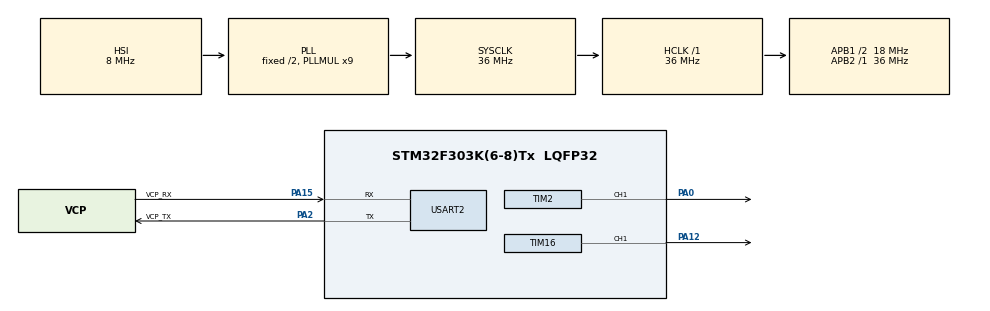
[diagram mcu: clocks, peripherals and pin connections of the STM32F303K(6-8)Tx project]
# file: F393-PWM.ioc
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Mcu.Family=STM32F3
Mcu.Name=STM32F303K(6-8)Tx
Mcu.Package=LQFP32
NVIC.PriorityGroup=NVIC_PRIORITYGROUP_4
PA0.Signal=S_TIM2_CH1_ETR
PA12.Signal=S_TIM16_CH1
PA13.GPIO_Label=SWDIO
PA13.Mode=Serial_Wire
PA13.Signal=SYS_JTMS-SWDIO
PA14.GPIO_Label=SWCLK
PA14.Mode=Serial_Wire
PA14.Signal=SYS_JTCK-SWCLK
PA15.GPIO_Label=VCP_RX
PA15.Mode=Asynchronous
PA15.Signal=USART2_RX
PA2.GPIO_Label=VCP_TX
PA2.Mode=Asynchronous
PA2.Signal=USART2_TX
PF0\ /\ OSC_IN.GPIO_Label=MCO
PF0\ /\ OSC_IN.Signal=RCC_OSC_IN
ProjectManager.HeapSize=0x200
ProjectManager.StackSize=0x400
ProjectManager.TargetToolchain=STM32CubeIDE
RCC.AHBFreq_Value=36000000
RCC.APB1CLKDivider=RCC_HCLK_DIV2
RCC.APB1Freq_Value=18000000
RCC.APB1TimFreq_Value=36000000
RCC.APB2Freq_Value=36000000
RCC.APB2TimFreq_Value=36000000
RCC.CortexFreq_Value=36000000
RCC.HCLKFreq_Value=36000000
RCC.HSE_VALUE=8000000
RCC.HSI_VALUE=8000000
RCC.PLLMUL=RCC_PLL_MUL9
RCC.SYSCLKFreq_VALUE=36000000
RCC.SYSCLKSourceVirtual=RCC_SYSCLKSOURCE_PLLCLK
SH.S_TIM16_CH1.0=TIM16_CH1,PWM Generation1 CH1
SH.S_TIM2_CH1_ETR.0=TIM2_CH1,PWM Generation1 CH1
TIM16.AutoReloadPreload=TIM_AUTORELOAD_PRELOAD_ENABLE
TIM16.Channel=TIM_CHANNEL_1
TIM16.Period=65535
TIM2.AutoReloadPreload=TIM_AUTORELOAD_PRELOAD_ENABLE
TIM2.Channel-PWM\ Generation1\ CH1=TIM_CHANNEL_1
TIM2.OCFastMode_PWM-PWM\ Generation1\ CH1=TIM_OCFAST_ENABLE
TIM2.OCPolarity_1=TIM_OCPOLARITY_HIGH
TIM2.Period=65535
USART2.VirtualMode-Asynchronous=VM_ASYNC
VP_TIM16_VS_ClockSourceINT.Mode=Enable_Timer
VP_TIM2_VS_ClockSourceINT.Mode=Internal
board=NUCLEO-F303K8

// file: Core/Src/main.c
/* USER CODE BEGIN Header */
/**
 ******************************************************************************
 * @file           : main.c
 * @brief          : Main program body
 ******************************************************************************
 * @attention
 *
 * Copyright (c) 2023 STMicroelectronics.
 * All rights reserved.
 *
 * This software is licensed under terms that can be found in the LICENSE file
 * in the root directory of this software component.
 * If no LICENSE file comes with this software, it is provided AS-IS.
 *
 ******************************************************************************
 */
/* USER CODE END Header */
#include "main.h"

TIM_HandleTypeDef htim2;
TIM_HandleTypeDef htim16;

UART_HandleTypeDef huart2;

void SystemClock_Config(void);
static void MX_GPIO_Init(void);
static void MX_USART2_UART_Init(void);
static void MX_TIM16_Init(void);
static void MX_TIM2_Init(void);

int main(void) {
	/* USER CODE BEGIN 1 */
	int32_t CH1_DC = 0;
	/* USER CODE END 1 */

	/* MCU Configuration--------------------------------------------------------*/

	/* Reset of all peripherals, Initializes the Flash interface and the Systick. */
	HAL_Init();

	/* Configure the system clock */
	SystemClock_Config();

	/* Initialize all configured peripherals */
	MX_GPIO_Init();
	MX_USART2_UART_Init();
	MX_TIM16_Init();
	MX_TIM2_Init();
	/* USER CODE BEGIN 2 */
	HAL_TIM_PWM_Start(&htim16, TIM_CHANNEL_1);
	HAL_TIM_PWM_Start(&htim2, TIM_CHANNEL_1);
	/* USER CODE END 2 */

	/* Infinite loop */
	/* USER CODE BEGIN WHILE */
	while (1) {
		while (CH1_DC < 65535) {
			TIM2->CCR1 = CH1_DC;
			CH1_DC += 70;
			HAL_Delay(1);
		}
		while (CH1_DC > 0) {
			TIM2->CCR1 = CH1_DC;
			CH1_DC -= 70;
			HAL_Delay(1);
		}
		/* USER CODE END WHILE */

	}
}

void SystemClock_Config(void) {
	RCC_OscInitTypeDef RCC_OscInitStruct = { 0 };
	RCC_ClkInitTypeDef RCC_ClkInitStruct = { 0 };

	/** Initializes the RCC Oscillators according to the specified parameters
	 * in the RCC_OscInitTypeDef structure.
	 */
	RCC_OscInitStruct.OscillatorType = RCC_OSCILLATORTYPE_HSI;
	RCC_OscInitStruct.HSIState = RCC_HSI_ON;
	RCC_OscInitStruct.HSICalibrationValue = RCC_HSICALIBRATION_DEFAULT;
	RCC_OscInitStruct.PLL.PLLState = RCC_PLL_ON;
	RCC_OscInitStruct.PLL.PLLSource = RCC_PLLSOURCE_HSI;
	RCC_OscInitStruct.PLL.PLLMUL = RCC_PLL_MUL9;
	if (HAL_RCC_OscConfig(&RCC_OscInitStruct) != HAL_OK) {
		Error_Handler();
	}

	/** Initializes the CPU, AHB and APB buses clocks
	 */
	RCC_ClkInitStruct.ClockType = RCC_CLOCKTYPE_HCLK | RCC_CLOCKTYPE_SYSCLK
			| RCC_CLOCKTYPE_PCLK1 | RCC_CLOCKTYPE_PCLK2;
	RCC_ClkInitStruct.SYSCLKSource = RCC_SYSCLKSOURCE_PLLCLK;
	RCC_ClkInitStruct.AHBCLKDivider = RCC_SYSCLK_DIV1;
	RCC_ClkInitStruct.APB1CLKDivider = RCC_HCLK_DIV2;
	RCC_ClkInitStruct.APB2CLKDivider = RCC_HCLK_DIV1;

	if (HAL_RCC_ClockConfig(&RCC_ClkInitStruct, FLASH_LATENCY_1) != HAL_OK) {
		Error_Handler();
	}
}

static void MX_TIM2_Init(void) {

	TIM_ClockConfigTypeDef sClockSourceConfig = { 0 };
	TIM_MasterConfigTypeDef sMasterConfig = { 0 };
	TIM_OC_InitTypeDef sConfigOC = { 0 };

	htim2.Instance = TIM2;
	htim2.Init.Prescaler = 0;
	htim2.Init.CounterMode = TIM_COUNTERMODE_UP;
	htim2.Init.Period = 65535;
	htim2.Init.ClockDivision = TIM_CLOCKDIVISION_DIV1;
	htim2.Init.AutoReloadPreload = TIM_AUTORELOAD_PRELOAD_ENABLE;
	if (HAL_TIM_Base_Init(&htim2) != HAL_OK) {
		Error_Handler();
	}
	sClockSourceConfig.ClockSource = TIM_CLOCKSOURCE_INTERNAL;
	if (HAL_TIM_ConfigClockSource(&htim2, &sClockSourceConfig) != HAL_OK) {
		Error_Handler();
	}
	if (HAL_TIM_PWM_Init(&htim2) != HAL_OK) {
		Error_Handler();
	}
	sMasterConfig.MasterOutputTrigger = TIM_TRGO_RESET;
	sMasterConfig.MasterSlaveMode = TIM_MASTERSLAVEMODE_DISABLE;
	if (HAL_TIMEx_MasterConfigSynchronization(&htim2, &sMasterConfig)
			!= HAL_OK) {
		Error_Handler();
	}
	sConfigOC.OCMode = TIM_OCMODE_PWM1;
	sConfigOC.Pulse = 0;
	sConfigOC.OCPolarity = TIM_OCPOLARITY_HIGH;
	sConfigOC.OCFastMode = TIM_OCFAST_ENABLE;
	if (HAL_TIM_PWM_ConfigChannel(&htim2, &sConfigOC, TIM_CHANNEL_1)
			!= HAL_OK) {
		Error_Handler();
	}
	HAL_TIM_MspPostInit(&htim2);

}

static void MX_TIM16_Init(void) {

	TIM_OC_InitTypeDef sConfigOC = { 0 };
	TIM_BreakDeadTimeConfigTypeDef sBreakDeadTimeConfig = { 0 };

	htim16.Instance = TIM16;
	htim16.Init.Prescaler = 0;
	htim16.Init.CounterMode = TIM_COUNTERMODE_UP;
	htim16.Init.Period = 65535;
	htim16.Init.ClockDivision = TIM_CLOCKDIVISION_DIV1;
	htim16.Init.RepetitionCounter = 0;
	htim16.Init.AutoReloadPreload = TIM_AUTORELOAD_PRELOAD_ENABLE;
	if (HAL_TIM_Base_Init(&htim16) != HAL_OK) {
		Error_Handler();
	}
	if (HAL_TIM_PWM_Init(&htim16) != HAL_OK) {
		Error_Handler();
	}
	sConfigOC.OCMode = TIM_OCMODE_PWM1;
	sConfigOC.Pulse = 0;
	sConfigOC.OCPolarity = TIM_OCPOLARITY_HIGH;
	sConfigOC.OCNPolarity = TIM_OCNPOLARITY_HIGH;
	sConfigOC.OCFastMode = TIM_OCFAST_DISABLE;
	sConfigOC.OCIdleState = TIM_OCIDLESTATE_RESET;
	sConfigOC.OCNIdleState = TIM_OCNIDLESTATE_RESET;
	if (HAL_TIM_PWM_ConfigChannel(&htim16, &sConfigOC, TIM_CHANNEL_1)
			!= HAL_OK) {
		Error_Handler();
	}
	sBreakDeadTimeConfig.OffStateRunMode = TIM_OSSR_DISABLE;
	sBreakDeadTimeConfig.OffStateIDLEMode = TIM_OSSI_DISABLE;
	sBreakDeadTimeConfig.LockLevel = TIM_LOCKLEVEL_OFF;
	sBreakDeadTimeConfig.DeadTime = 0;
	sBreakDeadTimeConfig.BreakState = TIM_BREAK_DISABLE;
	sBreakDeadTimeConfig.BreakPolarity = TIM_BREAKPOLARITY_HIGH;
	sBreakDeadTimeConfig.BreakFilter = 0;
	sBreakDeadTimeConfig.AutomaticOutput = TIM_AUTOMATICOUTPUT_DISABLE;
	if (HAL_TIMEx_ConfigBreakDeadTime(&htim16, &sBreakDeadTimeConfig)
			!= HAL_OK) {
		Error_Handler();
	}
	HAL_TIM_MspPostInit(&htim16);

}

static void MX_USART2_UART_Init(void) {

	huart2.Instance = USART2;
	huart2.Init.BaudRate = 38400;
	huart2.Init.WordLength = UART_WORDLENGTH_8B;
	huart2.Init.StopBits = UART_STOPBITS_1;
	huart2.Init.Parity = UART_PARITY_NONE;
	huart2.Init.Mode = UART_MODE_TX_RX;
	huart2.Init.HwFlowCtl = UART_HWCONTROL_NONE;
	huart2.Init.OverSampling = UART_OVERSAMPLING_16;
	huart2.Init.OneBitSampling = UART_ONE_BIT_SAMPLE_DISABLE;
	huart2.AdvancedInit.AdvFeatureInit = UART_ADVFEATURE_NO_INIT;
	if (HAL_UART_Init(&huart2) != HAL_OK) {
		Error_Handler();
	}

}

static void MX_GPIO_Init(void) {

	/* GPIO Ports Clock Enable */
	__HAL_RCC_GPIOF_CLK_ENABLE();
	__HAL_RCC_GPIOA_CLK_ENABLE();

}

void Error_Handler(void) {
	__disable_irq();
	while (1) {
	}
}
